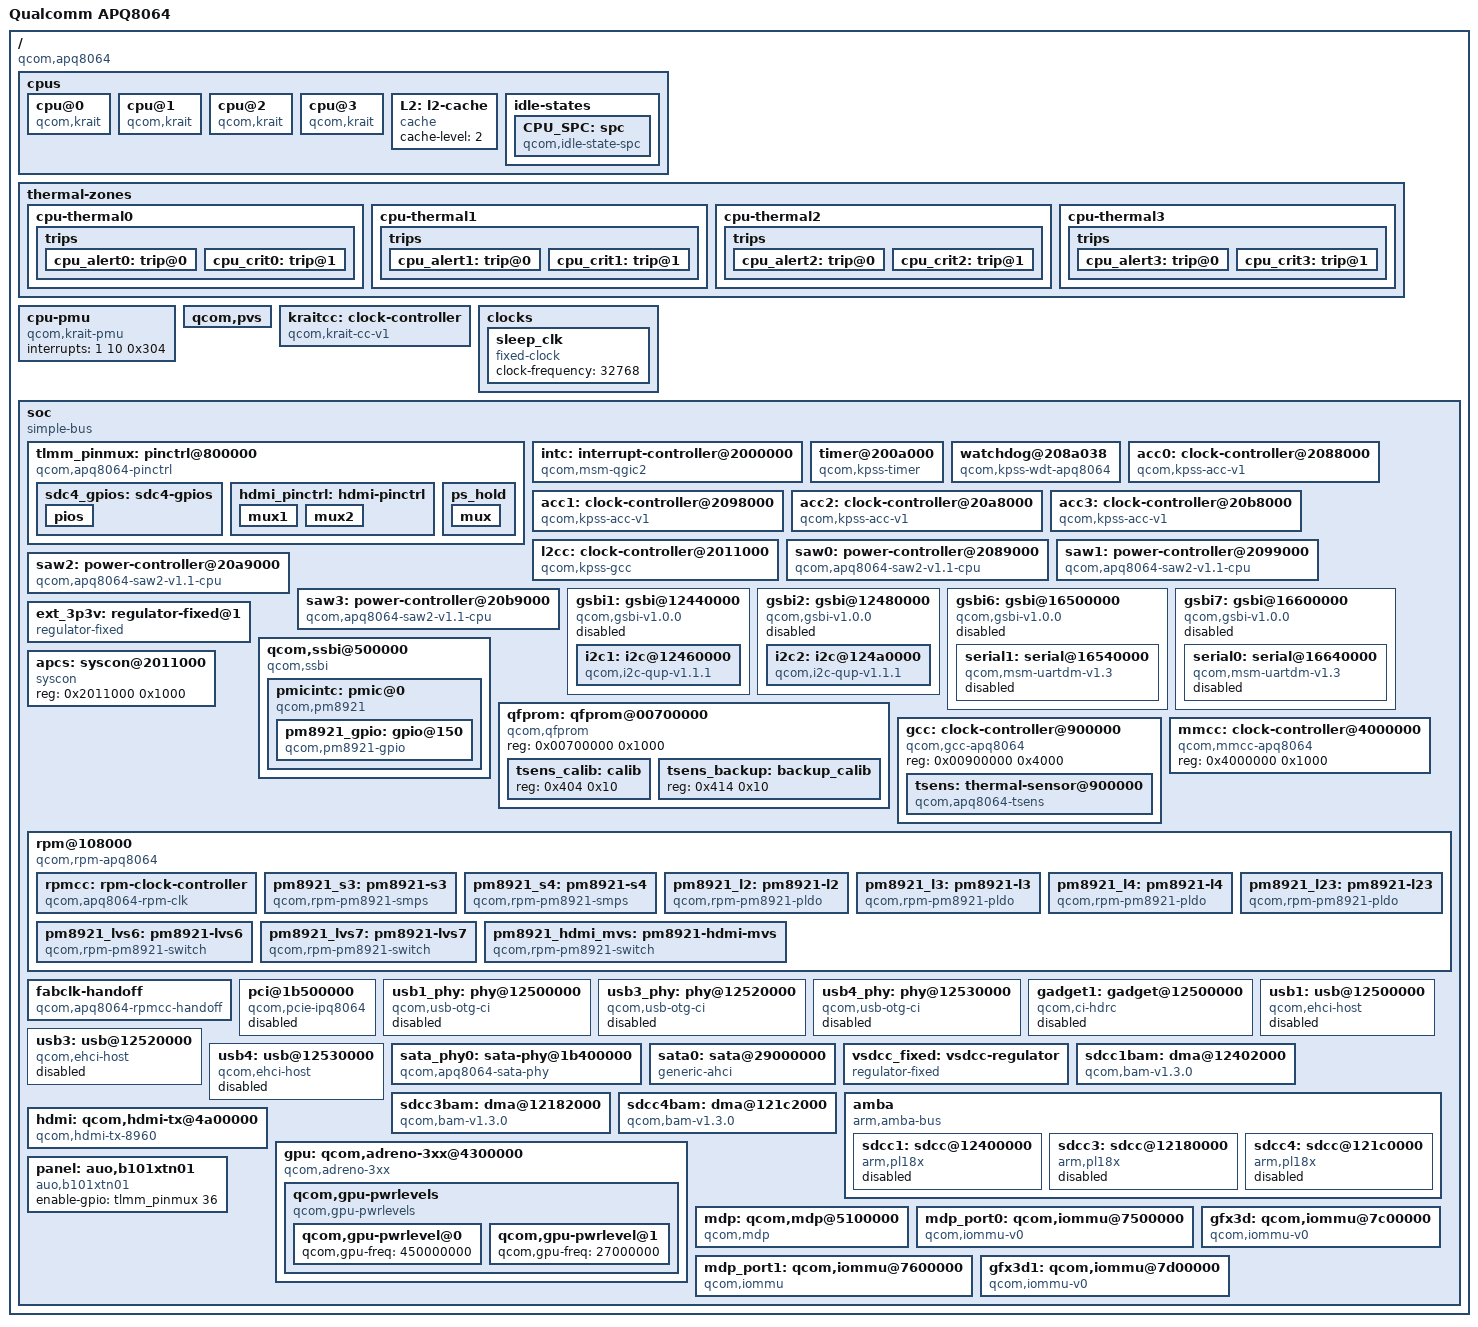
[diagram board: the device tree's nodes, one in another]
/dts-v1/;

#include "skeleton.dtsi"
#include <dt-bindings/gpio/gpio.h>
#include <dt-bindings/clock/qcom,gcc-msm8960.h>
#include <dt-bindings/reset/qcom,gcc-msm8960.h>
#include <dt-bindings/clock/qcom,mmcc-msm8960.h>
#include <dt-bindings/mfd/qcom-rpm.h>
#include <dt-bindings/soc/qcom,gsbi.h>
#include <dt-bindings/interrupt-controller/arm-gic.h>
#include <dt-bindings/gpio/gpio.h>
/ {
	model = "Qualcomm APQ8064";
	compatible = "qcom,apq8064";
	interrupt-parent = <&intc>;

	cpus {
		#address-cells = <1>;
		#size-cells = <0>;

		cpu@0 {
			compatible = "qcom,krait";
			enable-method = "qcom,kpss-acc-v1";
			device_type = "cpu";
			reg = <0>;
			next-level-cache = <&L2>;
			qcom,acc = <&acc0>;
			qcom,saw = <&saw0>;
			clocks = <&kraitcc 0>;
			clock-names = "cpu";
			clock-latency = <100000>;
			cpu-idle-states = <&CPU_SPC>;
		};

		cpu@1 {
			compatible = "qcom,krait";
			enable-method = "qcom,kpss-acc-v1";
			device_type = "cpu";
			reg = <1>;
			next-level-cache = <&L2>;
			qcom,acc = <&acc1>;
			qcom,saw = <&saw1>;
			clocks = <&kraitcc 1>;
			clock-names = "cpu";
			clock-latency = <100000>;
			cpu-idle-states = <&CPU_SPC>;
		};

		cpu@2 {
			compatible = "qcom,krait";
			enable-method = "qcom,kpss-acc-v1";
			device_type = "cpu";
			reg = <2>;
			next-level-cache = <&L2>;
			qcom,acc = <&acc2>;
			qcom,saw = <&saw2>;
			clocks = <&kraitcc 2>;
			clock-names = "cpu";
			clock-latency = <100000>;
			cpu-idle-states = <&CPU_SPC>;
		};

		cpu@3 {
			compatible = "qcom,krait";
			enable-method = "qcom,kpss-acc-v1";
			device_type = "cpu";
			reg = <3>;
			next-level-cache = <&L2>;
			qcom,acc = <&acc3>;
			qcom,saw = <&saw3>;
			clocks = <&kraitcc 3>;
			clock-names = "cpu";
			clock-latency = <100000>;
			cpu-idle-states = <&CPU_SPC>;
		};

		L2: l2-cache {
			compatible = "cache";
			cache-level = <2>;
		};

		idle-states {
			CPU_SPC: spc {
				compatible = "qcom,idle-state-spc",
						"arm,idle-state";
				entry-latency-us = <400>;
				exit-latency-us = <900>;
				min-residency-us = <3000>;
			};
		};
	};

	thermal-zones {
		cpu-thermal0 {
			polling-delay-passive = <250>;
			polling-delay = <1000>;

			thermal-sensors = <&tsens 7>;

			trips {
				cpu_alert0: trip@0 {
					temperature = <100000>;
					hysteresis = <2000>;
					type = "passive";
				};
				cpu_crit0: trip@1 {
					temperature = <125000>;
					hysteresis = <2000>;
					type = "critical";
				};
			};
		};

		cpu-thermal1 {
			polling-delay-passive = <250>;
			polling-delay = <1000>;

			thermal-sensors = <&tsens 8>;

			trips {
				cpu_alert1: trip@0 {
					temperature = <100000>;
					hysteresis = <2000>;
					type = "passive";
				};
				cpu_crit1: trip@1 {
					temperature = <125000>;
					hysteresis = <2000>;
					type = "critical";
				};
			};
		};

		cpu-thermal2 {
			polling-delay-passive = <250>;
			polling-delay = <1000>;

			thermal-sensors = <&tsens 9>;

			trips {
				cpu_alert2: trip@0 {
					temperature = <100000>;
					hysteresis = <2000>;
					type = "passive";
				};
				cpu_crit2: trip@1 {
					temperature = <125000>;
					hysteresis = <2000>;
					type = "critical";
				};
			};
		};

		cpu-thermal3 {
			polling-delay-passive = <250>;
			polling-delay = <1000>;

			thermal-sensors = <&tsens 10>;

			trips {
				cpu_alert3: trip@0 {
					temperature = <100000>;
					hysteresis = <2000>;
					type = "passive";
				};
				cpu_crit3: trip@1 {
					temperature = <125000>;
					hysteresis = <2000>;
					type = "critical";
				};
			};
		};
	};

	cpu-pmu {
		compatible = "qcom,krait-pmu";
		interrupts = <1 10 0x304>;
	};

	qcom,pvs {
		qcom,pvs-format-a;
		qcom,speed0-pvs0-bin-v0 =
			< 384000000 950000  >,
			< 486000000 975000  >,
			< 594000000 1000000  >,
			< 702000000 1025000  >,
			< 810000000 1075000  >,
			< 918000000 1100000  >;

		qcom,speed0-pvs1-bin-v0 =
			< 384000000 900000  >,
			< 486000000 925000  >,
			< 594000000 950000  >,
			< 702000000 975000  >,
			< 810000000 1025000  >,
			< 918000000 1050000  >;

		qcom,speed0-pvs3-bin-v0 =
			< 384000000 850000  >,
			< 486000000 875000  >,
			< 594000000 900000  >,
			< 702000000 925000  >,
			< 810000000 975000  >,
			< 918000000 1000000  >;

		qcom,speed0-pvs4-bin-v0 =
			< 384000000 850000  >,
			< 486000000 875000  >,
			< 594000000 900000  >,
			< 702000000 925000  >,
			< 810000000 962500  >,
			< 918000000 975000  >;

		qcom,speed1-pvs0-bin-v0 =
			< 384000000 950000  >,
			< 486000000 950000  >,
			< 594000000 950000  >,
			< 702000000 962500  >,
			< 810000000 1000000  >,
			< 918000000 1025000  >;

		qcom,speed1-pvs1-bin-v0 =
			< 384000000 950000  >,
			< 486000000 950000  >,
			< 594000000 950000  >,
			< 702000000 962500  >,
			< 810000000 975000  >,
			< 918000000 1000000  >;

		qcom,speed1-pvs2-bin-v0 =
			< 384000000 925000  >,
			< 486000000 925000  >,
			< 594000000 925000  >,
			< 702000000 925000  >,
			< 810000000 937500  >,
			< 918000000 950000  >;

		qcom,speed1-pvs3-bin-v0 =
			< 384000000 900000  >,
			< 486000000 900000  >,
			< 594000000 900000  >,
			< 702000000 900000  >,
			< 810000000 900000  >,
			< 918000000 925000  >;

		qcom,speed1-pvs4-bin-v0 =
			< 384000000 875000  >,
			< 486000000 875000  >,
			< 594000000 875000  >,
			< 702000000 875000  >,
			< 810000000 887500  >,
			< 918000000 900000  >;

		qcom,speed1-pvs5-bin-v0 =
			< 384000000 875000  >,
			< 486000000 875000  >,
			< 594000000 875000  >,
			< 702000000 875000  >,
			< 810000000 887500  >,
			< 918000000 900000  >;

		qcom,speed1-pvs6-bin-v0 =
			< 384000000 875000  >,
			< 486000000 875000  >,
			< 594000000 875000  >,
			< 702000000 875000  >,
			< 810000000 887500  >,
			< 918000000 900000  >;

		qcom,speed2-pvs0-bin-v0 =
			< 384000000 950000  >,
			< 486000000 950000  >,
			< 594000000 950000  >,
			< 702000000 950000  >,
			< 810000000 962500  >,
			< 918000000 975000  >;

		qcom,speed2-pvs1-bin-v0 =
			< 384000000 925000  >,
			< 486000000 925000  >,
			< 594000000 925000  >,
			< 702000000 925000  >,
			< 810000000 937500  >,
			< 918000000 950000  >;

		qcom,speed2-pvs2-bin-v0 =
			< 384000000 900000  >,
			< 486000000 900000  >,
			< 594000000 900000  >,
			< 702000000 900000  >,
			< 810000000 912500  >,
			< 918000000 925000  >;

		qcom,speed2-pvs3-bin-v0 =
			< 384000000 900000  >,
			< 486000000 900000  >,
			< 594000000 900000  >,
			< 702000000 900000  >,
			< 810000000 900000  >,
			< 918000000 912500  >;

		qcom,speed2-pvs4-bin-v0 =
			< 384000000 875000  >,
			< 486000000 875000  >,
			< 594000000 875000  >,
			< 702000000 875000  >,
			< 810000000 887500  >,
			< 918000000 900000  >;

		qcom,speed2-pvs5-bin-v0 =
			< 384000000 875000  >,
			< 486000000 875000  >,
			< 594000000 875000  >,
			< 702000000 875000  >,
			< 810000000 887500  >,
			< 918000000 900000  >;

		qcom,speed2-pvs6-bin-v0 =
			< 384000000 875000  >,
			< 486000000 875000  >,
			< 594000000 875000  >,
			< 702000000 875000  >,
			< 810000000 887500  >,
			< 918000000 900000  >;

		qcom,speed14-pvs0-bin-v0 =
			< 384000000 950000 >,
			< 486000000 950000 >,
			< 594000000 950000 >,
			< 702000000 962500 >,
			< 810000000 1000000 >,
			< 918000000 1025000 >;

		qcom,speed14-pvs1-bin-v0 =
			< 384000000 950000 >,
			< 486000000 950000 >,
			< 594000000 950000 >,
			< 702000000 962500 >,
			< 810000000 975000 >,
			< 918000000 1000000 >;

		qcom,speed14-pvs2-bin-v0 =
			< 384000000 925000 >,
			< 486000000 925000 >,
			< 594000000 925000 >,
			< 702000000 925000 >,
			< 810000000 937500 >,
			< 918000000 950000 >;

		qcom,speed14-pvs3-bin-v0 =
			< 384000000 900000 >,
			< 486000000 900000 >,
			< 594000000 900000 >,
			< 702000000 900000 >,
			< 810000000 900000 >,
			< 918000000 925000 >;

		qcom,speed14-pvs4-bin-v0 =
			< 384000000 875000 >,
			< 486000000 875000 >,
			< 594000000 875000 >,
			< 702000000 875000 >,
			< 810000000 887500 >,
			< 918000000 900000 >;

		qcom,speed14-pvs5-bin-v0 =
			< 384000000 875000 >,
			< 486000000 875000 >,
			< 594000000 875000 >,
			< 702000000 875000 >,
			< 810000000 887500 >,
			< 918000000 900000 >;

		qcom,speed14-pvs6-bin-v0 =
			< 384000000 875000 >,
			< 486000000 875000 >,
			< 594000000 875000 >,
			< 702000000 875000 >,
			< 810000000 887500 >,
			< 918000000 900000 >;
	};

	kraitcc: clock-controller {
		compatible = "qcom,krait-cc-v1";
		#clock-cells = <1>;
	};

	clocks {
		sleep_clk: sleep_clk {
			compatible = "fixed-clock";
			clock-frequency = <32768>;
			#clock-cells = <0>;
		};
	};

	soc: soc {
		#address-cells = <1>;
		#size-cells = <1>;
		ranges;
		compatible = "simple-bus";

		tlmm_pinmux: pinctrl@800000 {
			compatible = "qcom,apq8064-pinctrl";
			reg = <0x800000 0x4000>;

			gpio-controller;
			#gpio-cells = <2>;
			interrupt-controller;
			#interrupt-cells = <2>;
			interrupts = <0 16 IRQ_TYPE_LEVEL_HIGH>;

			pinctrl-names = "default";
			pinctrl-0 = <&ps_hold>;

			sdc4_gpios: sdc4-gpios {
				pios {
					pins = "gpio63", "gpio64", "gpio65", "gpio66", "gpio67", "gpio68";
					function = "sdc4";
				};
			};

			hdmi_pinctrl: hdmi-pinctrl {
				mux1 {
					pins = "gpio69", "gpio70", "gpio71";
					function = "hdmi";
					bias-pull-up;
					drive-strength = <2>;
				};
				mux2 {
					pins = "gpio72";
					function = "hdmi";
					bias-pull-down;
					drive-strength = <16>;
				};
			};
			ps_hold: ps_hold {
				mux {
					pins = "gpio78";
					function = "ps_hold";
				};
			};
		};

		intc: interrupt-controller@2000000 {
			compatible = "qcom,msm-qgic2";
			interrupt-controller;
			#interrupt-cells = <3>;
			reg = <0x02000000 0x1000>,
			      <0x02002000 0x1000>;
		};

		timer@200a000 {
			compatible = "qcom,kpss-timer", "qcom,msm-timer";
			interrupts = <1 1 0x301>,
				     <1 2 0x301>,
				     <1 3 0x301>;
			reg = <0x0200a000 0x100>;
			clock-frequency = <27000000>,
					  <32768>;
			cpu-offset = <0x80000>;
		};

		watchdog@208a038 {
			compatible = "qcom,kpss-wdt-apq8064";
			reg = <0x0208a038 0x40>;
			clocks = <&sleep_clk>;
			timeout-sec = <10>;
		};

		acc0: clock-controller@2088000 {
			compatible = "qcom,kpss-acc-v1";
			reg = <0x02088000 0x1000>, <0x02008000 0x1000>;
			clock-output-names = "acpu0_aux";
		};

		acc1: clock-controller@2098000 {
			compatible = "qcom,kpss-acc-v1";
			reg = <0x02098000 0x1000>, <0x02008000 0x1000>;
			clock-output-names = "acpu1_aux";
		};

		acc2: clock-controller@20a8000 {
			compatible = "qcom,kpss-acc-v1";
			reg = <0x020a8000 0x1000>, <0x02008000 0x1000>;
			clock-output-names = "acpu2_aux";
		};

		acc3: clock-controller@20b8000 {
			compatible = "qcom,kpss-acc-v1";
			reg = <0x020b8000 0x1000>, <0x02008000 0x1000>;
			clock-output-names = "acpu3_aux";
		};

		l2cc: clock-controller@2011000 {
			compatible = "qcom,kpss-gcc";
			reg = <0x2011000 0x1000>;
			clock-output-names = "acpu_l2_aux";
		};

		saw0: power-controller@2089000 {
			compatible = "qcom,apq8064-saw2-v1.1-cpu", "qcom,saw2";
			reg = <0x02089000 0x1000>, <0x02009000 0x1000>;
			regulator;
		};

		saw1: power-controller@2099000 {
			compatible = "qcom,apq8064-saw2-v1.1-cpu", "qcom,saw2";
			reg = <0x02099000 0x1000>, <0x02009000 0x1000>;
			regulator;
		};

		saw2: power-controller@20a9000 {
			compatible = "qcom,apq8064-saw2-v1.1-cpu", "qcom,saw2";
			reg = <0x020a9000 0x1000>, <0x02009000 0x1000>;
			regulator;
		};

		saw3: power-controller@20b9000 {
			compatible = "qcom,apq8064-saw2-v1.1-cpu", "qcom,saw2";
			reg = <0x020b9000 0x1000>, <0x02009000 0x1000>;
			regulator;
		};

		gsbi1: gsbi@12440000 {
			status = "disabled";
			compatible = "qcom,gsbi-v1.0.0";
			reg = <0x12440000 0x100>;
			clocks = <&gcc GSBI1_H_CLK>;
			clock-names = "iface";
			#address-cells = <1>;
			#size-cells = <1>;
			ranges;

			i2c1: i2c@12460000 {
				compatible = "qcom,i2c-qup-v1.1.1";
				reg = <0x12460000 0x1000>;
				interrupts = <0 194 IRQ_TYPE_NONE>;
				clocks = <&gcc GSBI1_QUP_CLK>, <&gcc GSBI1_H_CLK>;
				clock-names = "core", "iface";
				#address-cells = <1>;
				#size-cells = <0>;
			};
		};

		gsbi2: gsbi@12480000 {
			status = "disabled";
			compatible = "qcom,gsbi-v1.0.0";
			reg = <0x12480000 0x100>;
			clocks = <&gcc GSBI2_H_CLK>;
			clock-names = "iface";
			#address-cells = <1>;
			#size-cells = <1>;
			ranges;

			i2c2: i2c@124a0000 {
				compatible = "qcom,i2c-qup-v1.1.1";
				reg = <0x124a0000 0x1000>;
				interrupts = <0 196 IRQ_TYPE_NONE>;
				clocks = <&gcc GSBI2_QUP_CLK>, <&gcc GSBI2_H_CLK>;
				clock-names = "core", "iface";
				#address-cells = <1>;
				#size-cells = <0>;
			};
		};

		gsbi6: gsbi@16500000 {
			status = "disabled";
			compatible = "qcom,gsbi-v1.0.0";
			reg = <0x16500000 0x03>;
			clocks = <&gcc GSBI6_H_CLK>;
			clock-names = "iface";
			#address-cells = <1>;
			#size-cells = <1>;
			ranges;

			serial1: serial@16540000 {
				compatible = "qcom,msm-uartdm-v1.3", "qcom,msm-uartdm";
				reg = <0x16540000 0x100>,
				      <0x16500000 0x03>;
				interrupts = <0 156 0x0>;
				clocks = <&gcc GSBI6_UART_CLK>, <&gcc GSBI6_H_CLK>;
				clock-names = "core", "iface";
				status = "disabled";
			};
		};

		gsbi7: gsbi@16600000 {
			status = "disabled";
			compatible = "qcom,gsbi-v1.0.0";
			reg = <0x16600000 0x100>;
			clocks = <&gcc GSBI7_H_CLK>;
			clock-names = "iface";
			#address-cells = <1>;
			#size-cells = <1>;
			ranges;

			serial0: serial@16640000 {
				compatible = "qcom,msm-uartdm-v1.3", "qcom,msm-uartdm";
				reg = <0x16640000 0x1000>,
				      <0x16600000 0x1000>;
				interrupts = <0 158 0x0>;
				clocks = <&gcc GSBI7_UART_CLK>, <&gcc GSBI7_H_CLK>;
				clock-names = "core", "iface";
				status = "disabled";
			};
		};

		ext_3p3v: regulator-fixed@1 {
			compatible = "regulator-fixed";
			regulator-min-microvolt = <3300000>;
			regulator-max-microvolt = <3300000>;
			regulator-name = "ext_3p3v";
			regulator-type = "voltage";
			startup-delay-us = <0>;
			gpio = <&tlmm_pinmux 77 GPIO_ACTIVE_HIGH>;
			enable-active-high;
			regulator-boot-on;
		};

		qcom,ssbi@500000 {
			compatible = "qcom,ssbi";
			reg = <0x00500000 0x1000>;
			qcom,controller-type = "pmic-arbiter";

			pmicintc: pmic@0 {
				compatible = "qcom,pm8921";
				interrupt-parent = <&tlmm_pinmux>;
				interrupts = <74 8>;
				#interrupt-cells = <2>;
				interrupt-controller;
				#address-cells = <1>;
				#size-cells = <0>;
				pm8921_gpio: gpio@150 {

					compatible = "qcom,pm8921-gpio";
					reg = <0x150>;
					interrupts = <192 1>, <193 1>, <194 1>,
						     <195 1>, <196 1>, <197 1>,
						     <198 1>, <199 1>, <200 1>,
						     <201 1>, <202 1>, <203 1>,
						     <204 1>, <205 1>, <206 1>,
						     <207 1>, <208 1>, <209 1>,
						     <210 1>, <211 1>, <212 1>,
						     <213 1>, <214 1>, <215 1>,
						     <216 1>, <217 1>, <218 1>,
						     <219 1>, <220 1>, <221 1>,
						     <222 1>, <223 1>, <224 1>,
						     <225 1>, <226 1>, <227 1>,
						     <228 1>, <229 1>, <230 1>,
						     <231 1>, <232 1>, <233 1>,
						     <234 1>, <235 1>;

					gpio-controller;
					#gpio-cells = <2>;

				};
			};
		};

		qfprom: qfprom@00700000 {
			compatible	= "qcom,qfprom";
			reg		= <0x00700000 0x1000>;
			#address-cells	= <1>;
			#size-cells	= <1>;
			ranges;
			tsens_calib: calib {
				reg = <0x404 0x10>;
			};
			tsens_backup: backup_calib {
				reg = <0x414 0x10>;
			};
		};

		gcc: clock-controller@900000 {
			compatible = "qcom,gcc-apq8064";
			reg = <0x00900000 0x4000>;
			#clock-cells = <1>;
			#reset-cells = <1>;
			#address-cells	= <1>;
			#size-cells	= <1>;
			ranges;

			tsens: thermal-sensor@900000 {
				compatible = "qcom,apq8064-tsens";
				eeproms = <&tsens_calib>, <&tsens_backup>;
				eeprom-names = "calib", "backup_calib";
				qcom,tsens-slopes = <1176 1176 1154 1176 1111
					1132 1132 1199 1132 1199 1132>;
				#thermal-sensor-cells = <1>;
			};
		};

		mmcc: clock-controller@4000000 {
			compatible = "qcom,mmcc-apq8064";
			reg = <0x4000000 0x1000>;
			#clock-cells = <1>;
			#reset-cells = <1>;
		};

		apcs: syscon@2011000 {
			compatible = "syscon";
			reg = <0x2011000 0x1000>;
		};

		rpm@108000 {
			compatible	= "qcom,rpm-apq8064";
			reg		= <0x108000 0x1000>;
			qcom,ipc = <&apcs 0x8 2>;

			interrupts	= <0 19 0>, <0 21 0>, <0 22 0>;
			interrupt-names = "ack", "err", "wakeup";

			#address-cells	= <1>;
			#size-cells	= <0>;
			rpmcc: rpm-clock-controller {
				compatible	= "qcom,apq8064-rpm-clk";
				#clock-cells = <1>;
				#reset-cells = <1>;
			};

			pm8921_s3: pm8921-s3 {
				compatible	= "qcom,rpm-pm8921-smps";
				reg		= <QCOM_RPM_PM8921_SMPS3>;

				regulator-min-microvolt = <1000000>;
				regulator-max-microvolt = <1400000>;
				qcom,boot-load 		= <49360>;
				qcom,switch-mode-frequency = <3200000>;
				regulator-always-on;
			};

			pm8921_s4: pm8921-s4 {
				compatible	= "qcom,rpm-pm8921-smps";
				reg		= <QCOM_RPM_PM8921_SMPS4>;

				regulator-min-microvolt = <1800000>;
				regulator-max-microvolt = <1800000>;
				qcom,boot-load 		= <200000>;
				qcom,switch-mode-frequency = <3200000>;
				regulator-always-on;
			};

			pm8921_l2: pm8921-l2 {
				compatible	= "qcom,rpm-pm8921-pldo";
				reg		= <QCOM_RPM_PM8921_LDO2>;

// ???
				regulator-min-microvolt = <1200000>;
				regulator-max-microvolt = <1200000>;
				regulator-always-on;
//				qcom,boot-load = <50000>;
			};

			pm8921_l3: pm8921-l3 {
				compatible	= "qcom,rpm-pm8921-pldo";
				reg		= <QCOM_RPM_PM8921_LDO3>;

				regulator-min-microvolt = <3050000>;
				regulator-max-microvolt = <3300000>;
				regulator-always-on;
				qcom,boot-load = <50000>;
			};

			pm8921_l4: pm8921-l4 {
				compatible	= "qcom,rpm-pm8921-pldo";
				reg		= <QCOM_RPM_PM8921_LDO4>;

				regulator-min-microvolt = <1000000>;
				regulator-max-microvolt = <1800000>;
				regulator-always-on;
				qcom,boot-load = <50000>;
			};

			pm8921_l23: pm8921-l23 {
				compatible	= "qcom,rpm-pm8921-pldo";
				reg		= <QCOM_RPM_PM8921_LDO23>;

				regulator-min-microvolt = <1000000>;
				regulator-max-microvolt = <1800000>;
				qcom,boot-load = <50000>;
				regulator-always-on;
			};


			pm8921_lvs6: pm8921-lvs6 {
				compatible	= "qcom,rpm-pm8921-switch";
				reg		= <QCOM_RPM_PM8921_LVS6>;
				regulator-always-on;
			};

			pm8921_lvs7: pm8921-lvs7 {
				compatible	= "qcom,rpm-pm8921-switch";
				reg		= <QCOM_RPM_PM8921_LVS7>;
				regulator-always-on;
			};

			pm8921_hdmi_mvs: pm8921-hdmi-mvs {
				compatible	= "qcom,rpm-pm8921-switch";
				reg		= <QCOM_RPM_HDMI_SWITCH>;
				regulator-always-on;
				bias-pull-down;
			};

		};

		/* fabric clks handoff */
		fabclk-handoff{
			compatible	= "qcom,apq8064-rpmcc-handoff";
			clocks		= <&rpmcc QCOM_RPM_APPS_FABRIC_CLK>;

			assigned-clocks = <&rpmcc QCOM_RPM_APPS_FABRIC_CLK>;
			assigned-clock-rates = <0x7fffffff>;
		};

		/* PCIE */

		pci@1b500000 {
			compatible	= "qcom,pcie-ipq8064";
			reg		= <0x1b500000 0x1000>, <0x1b502000 0x100>, <0x1b600000 0x80>;
			reg-names	= "base", "elbi", "parf";
			status		= "disabled";
			#address-cells	= <3>;
			#size-cells	= <2>;
			device_type	= "pci";
			interrupts = <0 35 0x0
				 0 36 0x0
				 0 37 0x0
				 0 38 0x0
				 0 39 0x0
				 0 238 0x0>;
			interrupt-names = "irq1", "irq2", "irq3", "irq4", "iqr5", "msi";

			resets = <&gcc PCIE_ACLK_RESET>,
				 <&gcc PCIE_HCLK_RESET>,
				 <&gcc PCIE_POR_RESET>,
				 <&gcc PCIE_PCI_RESET>,
				 <&gcc PCIE_PHY_RESET>;
			reset-names = "axi", "ahb", "por", "pci", "phy";

			clocks = <&gcc PCIE_A_CLK>,
				 <&gcc PCIE_H_CLK>,
				 <&gcc PCIE_PHY_REF_CLK>;
			clock-names = "core", "iface", "phy";

			ranges = <0x00000000 0 0 0x0ff00000 0 0x00100000 /* configuration space */
				  0x81000000 0 0 0x0fe00000 0 0x00100000 /* downstream I/O */
				  0x82000000 0 0 0x08000000 0 0x07e00000>; /* non-prefetchable memory */

		};



		usb1_phy:phy@12500000 {
			compatible	= "qcom,usb-otg-ci";
			reg		= <0x12500000 0x400>;
			interrupts	= <0 100 0>;
			status		= "disabled";
			dr_mode		= "host";

			clocks		= <&gcc USB_HS1_XCVR_CLK>,
					  <&gcc USB_HS1_H_CLK>;
			clock-names	= "core", "iface";

			vddcx-supply	= <&pm8921_s3>;
			v3p3-supply	= <&pm8921_l3>;
			v1p8-supply	= <&pm8921_l4>;

			resets		= <&gcc USB_HS1_RESET>;
			reset-names	= "link";
		};

		usb3_phy:phy@12520000 {
			compatible	= "qcom,usb-otg-ci";
			reg		= <0x12520000 0x400>;
			interrupts	= <0 188 0>;
			status		= "disabled";
			dr_mode		= "host";

			clocks		= <&gcc USB_HS3_XCVR_CLK>,
					  <&gcc USB_HS3_H_CLK>;
			clock-names	= "core", "iface";

			vddcx-supply	= <&pm8921_s3>;
			v3p3-supply	= <&pm8921_l3>;
			v1p8-supply	= <&pm8921_l23>;

			resets		= <&gcc USB_HS3_RESET>;
			reset-names	= "link";
		};

		usb4_phy:phy@12530000 {
			compatible	= "qcom,usb-otg-ci";
			reg		= <0x12530000 0x400>;
			interrupts	= <0 215 0>;
			status		= "disabled";
			dr_mode		= "host";

			clocks		= <&gcc USB_HS4_XCVR_CLK>,
					  <&gcc USB_HS4_H_CLK>;
			clock-names	= "core", "iface";

			vddcx-supply	= <&pm8921_s3>;
			v3p3-supply	= <&pm8921_l3>;
			v1p8-supply	= <&pm8921_l23>;

			resets		= <&gcc USB_HS4_RESET>;
			reset-names	= "link";
		};

		gadget1:gadget@12500000 {
			compatible	= "qcom,ci-hdrc";
			reg		= <0x12500000 0x400>;
			status		= "disabled";
			dr_mode		= "peripheral";
			interrupts	= <0 100 0>;
			usb-phy		= <&usb1_phy>;
		};

		usb1: usb@12500000 {
			compatible	= "qcom,ehci-host";
			reg		= <0x12500000 0x400>;
			interrupts	= <0 100 0>;
			status		= "disabled";
			usb-phy		= <&usb1_phy>;
		};

		usb3: usb@12520000 {
			compatible	= "qcom,ehci-host";
			reg		= <0x12520000 0x400>;
			interrupts	= <0 188 0>;
			status		= "disabled";
			usb-phy		= <&usb3_phy>;
		};

		usb4: usb@12530000 {
			compatible	= "qcom,ehci-host";
			reg		= <0x12530000 0x400>;
			interrupts	= <0 215 0>;
			status		= "disabled";
			usb-phy		= <&usb4_phy>;
		};

		sata_phy0:sata-phy@1b400000{
			compatible	= "qcom,apq8064-sata-phy";
			reg		= <0x1b400000 0x200>;
			reg-names	= "phy_mem";
			clocks		= <&gcc SATA_PHY_CFG_CLK>;
			clock-names = "cfg";
			#phy-cells = <0>;
		};

		sata0: sata@29000000 {
			compatible	= "generic-ahci";
			reg		= <0x29000000 0x180>;
			interrupts	= <0 209 0>;
			clocks = <&gcc SFAB_SATA_S_H_CLK>, <&gcc SATA_H_CLK>,
				 <&gcc SATA_A_CLK>, <&gcc SATA_RXOOB_CLK>,
				 <&gcc SATA_PMALIVE_CLK>;

			clock-names = "slave_iface", "iface",
				      "bus", "rxoob",
				      "core_pmalive";
			assigned-clocks = <&gcc SATA_RXOOB_CLK>,
						<&gcc SATA_PMALIVE_CLK>;
			assigned-clock-rates = <100000000>, <100000000>;

			phys  = <&sata_phy0>;
			phy-names = "sata-phy";
			target-supply = <&pm8921_s4>;
		};

		/* Temporary fixed regulator */
		vsdcc_fixed: vsdcc-regulator {
			compatible = "regulator-fixed";
			regulator-name = "SDCC Power";
			regulator-min-microvolt = <2700000>;
			regulator-max-microvolt = <2700000>;
			regulator-always-on;
		};

		sdcc1bam:dma@12402000{
			compatible = "qcom,bam-v1.3.0";
			reg = <0x12402000 0x8000>;
			interrupts = <0 98 0>;
			clocks = <&gcc SDC1_H_CLK>;
			clock-names = "bam_clk";
			#dma-cells = <1>;
			qcom,ee = <0>;
		};

		sdcc3bam:dma@12182000{
			compatible = "qcom,bam-v1.3.0";
			reg = <0x12182000 0x8000>;
			interrupts = <0 96 0>;
			clocks = <&gcc SDC3_H_CLK>;
			clock-names = "bam_clk";
			#dma-cells = <1>;
			qcom,ee = <0>;
		};

		sdcc4bam:dma@121c2000{
			compatible = "qcom,bam-v1.3.0";
			reg = <0x121c2000 0x8000>;
			interrupts = <0 95 0>;
			clocks = <&gcc SDC4_H_CLK>;
			clock-names = "bam_clk";
			#dma-cells = <1>;
			qcom,ee = <0>;
		};

		amba {
			compatible = "arm,amba-bus";
			#address-cells = <1>;
			#size-cells = <1>;
			ranges;
			sdcc1: sdcc@12400000 {
				status		= "disabled";
				compatible	= "arm,pl18x", "arm,primecell";
				arm,primecell-periphid = <0x00051180>;
				reg		= <0x12400000 0x2000>;
				interrupts	= <GIC_SPI 104 IRQ_TYPE_LEVEL_HIGH>;
				interrupt-names	= "cmd_irq";
				clocks		= <&gcc SDC1_CLK>, <&gcc SDC1_H_CLK>;
				clock-names	= "mclk", "apb_pclk";
				bus-width	= <8>;
				max-frequency	= <96000000>;
				non-removable;
				cap-sd-highspeed;
				cap-mmc-highspeed;
				vmmc-supply = <&vsdcc_fixed>;
				dmas = <&sdcc1bam 2>, <&sdcc1bam 1>;
				dma-names = "tx", "rx";
			};

			sdcc3: sdcc@12180000 {
				compatible	= "arm,pl18x", "arm,primecell";
				arm,primecell-periphid = <0x00051180>;
				status		= "disabled";
				reg		= <0x12180000 0x2000>;
				interrupts	= <GIC_SPI 102 IRQ_TYPE_LEVEL_HIGH>;
				interrupt-names	= "cmd_irq";
				clocks		= <&gcc SDC3_CLK>, <&gcc SDC3_H_CLK>;
				clock-names	= "mclk", "apb_pclk";
				bus-width	= <4>;
				cap-sd-highspeed;
				cap-mmc-highspeed;
				max-frequency	= <192000000>;
				no-1-8-v;
				vmmc-supply = <&vsdcc_fixed>;
				dmas = <&sdcc3bam 2>, <&sdcc3bam 1>;
				dma-names = "tx", "rx";
			};

			sdcc4: sdcc@121c0000 {
				compatible	= "arm,pl18x", "arm,primecell";
				arm,primecell-periphid = <0x00051180>;
				status		= "disabled";
				reg		= <0x121c0000 0x2000>;
				interrupts	= <GIC_SPI 101 IRQ_TYPE_LEVEL_HIGH>;
				interrupt-names	= "cmd_irq";
				clocks		= <&gcc SDC4_CLK>, <&gcc SDC4_H_CLK>;
				clock-names	= "mclk", "apb_pclk";
				bus-width	= <4>;
				cap-sd-highspeed;
				cap-mmc-highspeed;
				max-frequency	= <48000000>;
				vmmc-supply = <&vsdcc_fixed>;
				vqmmc-supply = <&vsdcc_fixed>;
				dmas = <&sdcc4bam 2>, <&sdcc4bam 1>;
				dma-names = "tx", "rx";
				pinctrl-names = "default";
				pinctrl-0 = <&sdc4_gpios>;
			};
		};

		hdmi: qcom,hdmi-tx@4a00000 {
			compatible = "qcom,hdmi-tx-8960";
			reg-names = "core_physical";
			reg = <0x04a00000 0x1000>;
			interrupts = <GIC_SPI 79 0>;
			clock-names =
			    "core_clk",
			    "master_iface_clk",
			    "slave_iface_clk";
			clocks =
			    <&mmcc HDMI_APP_CLK>,
			    <&mmcc HDMI_M_AHB_CLK>,
			    <&mmcc HDMI_S_AHB_CLK>;
			qcom,hdmi-tx-ddc-clk = <&tlmm_pinmux 70 GPIO_ACTIVE_HIGH>;
			qcom,hdmi-tx-ddc-data = <&tlmm_pinmux 71 GPIO_ACTIVE_HIGH>;
			qcom,hdmi-tx-hpd = <&tlmm_pinmux 72 GPIO_ACTIVE_HIGH>;
			core-vdda-supply = <&pm8921_hdmi_mvs>;
			hdmi-mux-supply = <&ext_3p3v>;
			pinctrl-names = "default";
			pinctrl-0 = <&hdmi_pinctrl>;
		};

		gpu: qcom,adreno-3xx@4300000 {
			compatible = "qcom,adreno-3xx";
			#stream-id-cells = <16>;
			reg = <0x04300000 0x20000>;
			reg-names = "kgsl_3d0_reg_memory";
			interrupts = <GIC_SPI 80 0>;
			interrupt-names = "kgsl_3d0_irq";
			clock-names =
			    "core_clk",
			    "iface_clk",
			    "mem_clk",
			    "mem_iface_clk";
			clocks =
			    <&mmcc GFX3D_CLK>,
			    <&mmcc GFX3D_AHB_CLK>,
			    <&mmcc GFX3D_AXI_CLK>,
			    <&mmcc MMSS_IMEM_AHB_CLK>;
			qcom,chipid = <0x03020002>;
			qcom,gpu-pwrlevels {
				compatible = "qcom,gpu-pwrlevels";
				qcom,gpu-pwrlevel@0 {
					qcom,gpu-freq = <450000000>;
				};
				qcom,gpu-pwrlevel@1 {
					qcom,gpu-freq = <27000000>;
				};
			};
		};

		panel: auo,b101xtn01 {
			compatible = "auo,b101xtn01";
			// lcd1_pwr_en_n:
			enable-gpio = <&tlmm_pinmux 36 GPIO_ACTIVE_HIGH>;
		};

		mdp: qcom,mdp@5100000 {
			compatible = "qcom,mdp";
			#stream-id-cells = <2>;
			reg = <0x05100000 0xf0000>;
			interrupts = <GIC_SPI 75 0>;
			connectors = <&hdmi>;
			gpus = <&gpu>;
			qcom,lvds-panel = <&panel>;
			clock-names =
			    "core_clk",
			    "iface_clk",
			    "lut_clk",
			    "src_clk",
			    "hdmi_clk",
			    "mdp_clk",
			    "mdp_axi_clk";
			clocks =
			    <&mmcc MDP_CLK>,
			    <&mmcc MDP_AHB_CLK>,
			    <&mmcc MDP_LUT_CLK>,
			    <&mmcc TV_SRC>,
			    <&mmcc HDMI_TV_CLK>,
			    <&mmcc MDP_TV_CLK>,
			    <&mmcc MDP_AXI_CLK>;
//			vdd-supply = <&footswitch_mdp>;
			lvds-vccs-3p3v-supply = <&ext_3p3v>;
			lvds-pll-vdda-supply = <&pm8921_l2>;
			lvds-vdda-supply = <&pm8921_lvs7>;
		};

		mdp_port0: qcom,iommu@7500000 {
			compatible = "qcom,iommu-v0";
			clock-names =
			    "smmu_pclk",
			    "iommu_clk";
			clocks =
			    <&mmcc SMMU_AHB_CLK>,
			    <&mmcc MDP_AXI_CLK>;
			reg-names = "physbase";
			reg = <0x07500000 0x100000>;
			interrupt-names =
			    "secure_irq",
			    "nonsecure_irq";
			interrupts =
			    <GIC_SPI 63 0>,
			    <GIC_SPI 64 0>;
			ncb = <2>;
			mmu-masters = <&mdp 0 2>;
		};

		mdp_port1: qcom,iommu@7600000 {
			compatible = "qcom,iommu";
			clock-names =
			    "smmu_pclk",
			    "iommu_clk";
			clocks =
			    <&mmcc SMMU_AHB_CLK>,
			    <&mmcc MDP_AXI_CLK>;
			reg-names = "physbase";
			reg = <0x07600000 0x100000>;
			interrupt-names =
			    "secure_irq",
			    "nonsecure_irq";
			interrupts =
			    <GIC_SPI 61 0>,
			    <GIC_SPI 62 0>;
			ncb = <2>;
			mmu-masters = <&mdp 0 2>;
		};

		gfx3d: qcom,iommu@7c00000 {
			compatible = "qcom,iommu-v0";
			clock-names =
			    "smmu_pclk",
			    "iommu_clk";
			clocks =
			    <&mmcc SMMU_AHB_CLK>,
			    <&mmcc GFX3D_AXI_CLK>;
			reg-names = "physbase";
			reg = <0x07c00000 0x100000>;
			interrupt-names =
			    "secure_irq",
			    "nonsecure_irq";
			interrupts =
			    <GIC_SPI 69 0>,
			    <GIC_SPI 70 0>;
			ncb = <3>;
			ttbr-split = <1>;
			mmu-masters =
			    /* gfx3d_user: */
			    <&gpu 0 1 2 3 4 5 6 7 8 9 10 11 12 13 14 15>,
			    /* gfx3d_priv: */
			    <&gpu 16 17 18 19 20 21 22 23 24 25 26 27 28 29 30 31>;
		};

		gfx3d1: qcom,iommu@7d00000 {
			compatible = "qcom,iommu-v0";
			clock-names =
			    "smmu_pclk",
			    "iommu_clk";
			clocks =
			    <&mmcc SMMU_AHB_CLK>,
			    <&mmcc GFX3D_AXI_CLK>;
			reg-names = "physbase";
			reg = <0x07d00000 0x100000>;
			interrupt-names =
			    "secure_irq",
			    "nonsecure_irq";
			interrupts =
			    <GIC_SPI 210 0>,
			    <GIC_SPI 211 0>;
			ncb = <3>;
			ttbr-split = <1>;
			mmu-masters =
			    /* gfx3d_user: */
			    <&gpu 0 1 2 3 4 5 6 7 8 9 10 11 12 13 14 15>,
			    /* gfx3d_priv: */
			    <&gpu 16 17 18 19 20 21 22 23 24 25 26 27 28 29 30 31>;
		};
	};
};
